# DP32G030 register map
File version: 1.0
CPU: CM0 r0p0, little endian, no MPU, no FPU, 4 interrupt priority bits
Registers are 32-bit, read-write, reset 0x0 unless marked. A register's access mark holds for its fields unless they carry their own. Offsets are from the block's base; [hi:lo] are bit positions.

## PORTCON — PORTCON unit
Base 0x400B0000
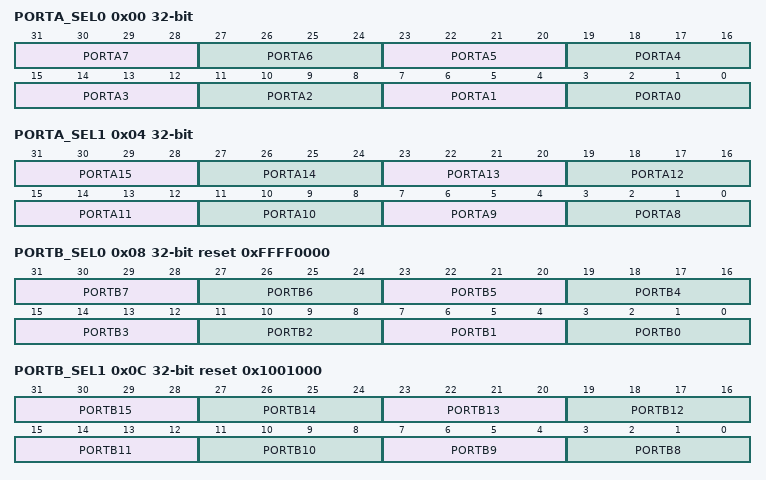
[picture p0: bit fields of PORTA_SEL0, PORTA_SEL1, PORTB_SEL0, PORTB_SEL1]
0x00 PORTA_SEL0 — PORTA Function Select Register0
  [31:28] PORTA7 — Port configuration 0000: GPIOA7 0001: UART1_TX 0010: timerp0_in0 0011: timerp0_out_l 0100: SARADC_CH2 0101: OPA0_VP
  [27:24] PORTA6 — Port configuration 0000: GPIOA6 0001: UART1_RTS 0010: TIMERP1_IN1 0011: timerp1_out_h 0100: SARADC_CH1 0101: OPA0_OUT
  [23:20] PORTA5 — Port configuration 0000: GPIOA5 0001: UART1_CTS 0010: PWMP1_PLUS1 0011: TIMERP1_IN0 0100: timerp1_out_l 0101: WAKEUP1 0110: SARADC_CH0
  [19:16] PORTA4 — Port configuration 000: GPIOA4 001: CMP0_VP 010: XTAH_XO
  [15:12] PORTA3 — Port configuration 000: GPIOA3 001: CMP0_VN
  [11:8] PORTA2 — Port configuration 000: GPIOA2 001: XTAL_XO
  [7:4] PORTA1 — Port configuration 000: GPIOA1 001: XTAL_XI
  [3:0] PORTA0 — 0000: GPIOA0 0001: PWMP1_PLUS0 0010: PWMP0_PLUS1 0011: TM 0100: WAKEUP0
0x04 PORTA_SEL1 — PORTA Function Select Register1
  [31:28] PORTA15 — 0000: GPIOA15 0001: PWMB1_CH1 0010: PWMP0_CH0 0011: TIMERP1_IN1 0100: timerp1_out_h
  [27:24] PORTA14 — 0000: GPIOA14 0001: PWMB1_CH0 0010: PWMP0_CH2N 0011: TIMERP1_IN0 0100: timerp1_out_l 0101: SARADC_CH9
  [23:20] PORTA13 — 0000: GPIOA13 0001: PWMB0_CH2 0010: PWMP0_CH1N 0011: timerp0_in1 0100: timerp0_out_h 0101: SARADC_CH8
  [19:16] PORTA12 — 0000: GPIOA12 0001: SPI0_MOSI 0010: PWMB0_CH1 0011: PWMP0_CH0N 0100: TIMERP0_IN0 0101: timerp0_out_l 0110: SARADC_CH7
  [15:12] PORTA11 — 0000: GPIOA11 0001: SPI0_MISO 0010: PWMB0_CH0 0011: PWMP0_BRAKE0 0100: TIMERP1_IN1 0101: timerp1_out_h 0110: SARADC_CH6
  [11:8] PORTA10 — 0000: GPIOA10 0001: SPI0_CLK 0010: SARADC_CH5 0011: CMP1_VP
  [7:4] PORTA9 — 0000: GPIOA9 0001: SPI0_SSN 0010: TIMERP1_IN0 0011: timerp1_out_l 0100: TM 0101: SARADC_CH4 0110: CMP1_VN
  [3:0] PORTA8 — 0000: GPIOA8 0001: UART1_RX 0010: timerp0_in1 0011: timerp0_out_h 0100: SARADC_CH3 0101: OPA0_VN
0x08 PORTB_SEL0 reset 0xFFFF0000 — PORTB Function Select Register0
  [31:28] PORTB7 — 0000: GPIOB7 0001: SPI0_SSN 0010: UART0_TX 0011: IIC0_SCL 0100: PWMP1_BRAKE0 0101: PWMP0_CH1
  [27:24] PORTB6 — 0000: GPIOB6 0001: PWMP0_CH0 0010: timerp0_in1 0011: timerp0_out_h
  [23:20] PORTB5 — 0000: GPIOB5 0001: SPI1_MOSI 0010: PWMP1_CH0N 0011: PWMP0_CH2N 0100: TIMERP0_IN0 0101: timerp0_out_l
  [19:16] PORTB4 — 0000: GPIOB4 0001: SPI1_MISO 0010: IIC1_SCL 0011: PWMP1_CH0 0100: PWMP0_CH1N 0101: timerp1_hall2
  [15:12] PORTB3 — 0000: GPIOB3 0001: SPI1_CLK 0010: IIC1_SDA 0011: PWMP0_CH0N 0100: TIMERP1_HALL1
  [11:8] PORTB2 — 0000: GPIOB2 0001: SPI1_SSN 0010: PWMP0_BRAKE1 0011: TIMERP1_HALL0
  [7:4] PORTB1 — 0000: GPIOB1 0001: UART2_RX 0010: IIC0_SDA 0011: PWMP0_CH2
  [3:0] PORTB0 — 0000: GPIOB0 0001: UART2_TX 0010: IIC0_SCL 0011: PWMB1_CH2 0100: PWMP0_CH1
0x0C PORTB_SEL1 reset 0x1001000 — PORTB Function Select Register1
  [31:28] PORTB15 — FUNCTION
  [27:24] PORTB14 — 0001:SWCLK
  [23:20] PORTB13 — FUNCTION
  [19:16] PORTB12 — FUNCTION
  [15:12] PORTB11 — 0001:SWDIO
  [11:8] PORTB10 — FUNCTION
  [7:4] PORTB9 — FUNCTION
  [3:0] PORTB8 — FUNCTION
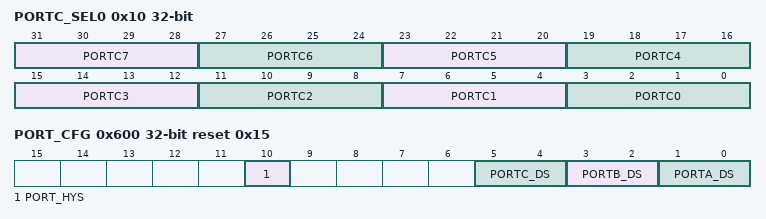
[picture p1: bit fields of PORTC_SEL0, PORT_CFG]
0x10 PORTC_SEL0 — PORTC Function Select Register0
  [31:28] PORTC7 — 0000: GPIOC7 0001: IIC1_SDA 0010: PWMP1_CH2 0011: TIMERP1_IN0 0100: timerp1_out_l 0101: OPA1_OUT
  [27:24] PORTC6 — 0000: GPIOC6 0001: IIC1_SCL 0010: PWMP1_CH1 0011: TIMERP1_IN1 0100: timerp1_out_h 0101: OPA1_VN
  [23:20] PORTC5 — 0000: GPIOC5 0001: timerp0_hall2 0010: TM 0011: OPA1_VP
  [19:16] PORTC4 — 0000: GPIOC4 0001: UART0_RX 0010: IIC0_SDA 0011: PWMP1_CH2N 0100: TIMERP0_HALL1 0101: CMP2_VP
  [15:12] PORTC3 — 0000: GPIOC3 0001: UART0_TX 0010: IIC0_SCL 0011: PWMP1_CH1N 0100: TIMERP0_HALL0 0101: CMP2_VN
  [11:8] PORTC2 — 0000: GPIOC2 0001: SPI1_MOSI 0010: PWMB1_CH2 0011: PWMP1_BRAKE2 0100: TIMERP0_IN1 0101: timerp0_out_h
  [7:4] PORTC1 — 0000: GPIOC1 0001: SPI1_MISO 0010: UART2_RTS 0011: PWMB1_CH1 0100: TIMERP0_IN0 0101: timerp0_out_l
  [3:0] PORTC0 — 0000: GPIOC0 0001: SPI1_CLK 0010: UART2_CTS 0011: PWMB1_CH0
0x100 PORTA_IE — PORTA Input enable register
  [15:0] PORTA_IE — PORTA Input Enable Register 0: disable 1: Enable (each bit corresponds to 1 IO, bit0 corresponds to A0, bit1 corresponds to A1)
0x104 PORTB_IE reset 0x4800 — PORTB Input enable register
  [15:0] PORTB_IE — PORTB Input Enable Register 0: disable 1: Enable (each bit corresponds to 1 IO, bit0 corresponds to B0, bit1 corresponds to B1)
0x108 PORTC_IE reset 0x20 — PORTC Input enable register
  [7:0] PORTC_IE — PORTC Input Enable Register 0: disable 1: Enable (each bit corresponds to 1 IO, bit0 corresponds to C0, bit1 corresponds to C1)
0x200 PORTA_PU — PORTA pull-up enable register
  [15:0] PORTA_PU — PORTA Pull-up Enable Register 0: disable 1: Enable (each bit corresponds to 1 IO, bit0 corresponds to A0, bit1 corresponds to A1)
0x204 PORTB_PU — PORTB pull-up enable register
  [15:0] PORTB_PU — PORTB Pull-up Enable Register 0: disable 1: Enable (each bit corresponds to 1 IO, bit0 corresponds to B0, bit1 corresponds to B1)
0x208 PORTC_PU — PORTC pull-up enable register
  [7:0] PORTC_PU — PORTC Pull-up Enable Register 0: disable 1: Enable (each bit corresponds to 1 IO, bit0 corresponds to C0, bit1 corresponds to C1)
0x300 PORTA_PD — PORTA pull-down enable register
  [15:0] PORTA_PD — PORTA Pull-down Enable Register 0: disable 1: Enable (each bit corresponds to 1 IO, bit0 corresponds to A0, bit1 corresponds to A1)
0x304 PORTB_PD — PORTB pull-down enable register
  [15:0] PORTB_PD — PORTB Pull-down Enable Register 0: disable 1: Enable (each bit corresponds to 1 IO, bit0 corresponds to B0, bit1 corresponds to B1)
0x308 PORTC_PD reset 0x20 — PORTC pull-down enable register
  [7:0] PORTC_PD — PORTC Pull-down Enable Register 0: disable 1: Enable (each bit corresponds to 1 IO, bit0 corresponds to C0, bit1 corresponds to C1)
0x400 PORTA_OD — PORTA Open Drain Enable Register
  [15:0] PORTA_OD — PORTA Open Drain Enable Register 0: disable 1: Enable (each bit corresponds to 1 IO, bit0 corresponds to A0, bit1 corresponds to A1)
0x404 PORTB_OD — PORTB Open Drain Enable Register
  [15:0] PORTB_OD — PORTB Open Drain Enable Register 0: disable 1: Enable (each bit corresponds to 1 IO, bit0 corresponds to B0, bit1 corresponds to B1)
0x408 PORTC_OD — PORTC Open Drain Enable Register
  [7:0] PORTC_OD — PORTC Open Drain Enable Register 0: disable 1: Enable (each bit corresponds to 1 IO, bit0 corresponds to C0, bit1 corresponds to C1)
0x500 PORTA_WKE — PORTA wakeup enable register
  [15:0] PORTA_WKE — PORTA Wake-up Enable Register 0: disable 1: Enable (each bit corresponds to 1 IO, bit0 corresponds to A0, bit1 corresponds to A1)
0x504 PORTB_WKE — PORTB wakeup enable register
  [15:0] PORTB_WKE — PORTB Wake-up Enable Register 0: disable 1: Enable (each bit corresponds to 1 IO, bit0 corresponds to B0, bit1 corresponds to B1)
0x508 PORTC_WKE — PORTC wakeup enable register
  [7:0] PORTC_WKE — PORTC Wake-up Enable Register 0: disable 1: Enable (each bit corresponds to 1 IO, bit0 corresponds to C0, bit1 corresponds to C1)
0x600 PORT_CFG reset 0x15 — port configuration register
  [10] PORT_HYS — PORT Input hysteresis level selection 0: low input hysteresis (input signal greater than 0.7VDD and less than 0.3VDD) 1: high input hysteresis (input signal greater than 0.85VDD and less than 0.15VDD)
  [5:4] PORTC_DS — PORTC Driveability Selection Register 00: 5mA 01: 10mA 10: 15mA 11: 20mA
  [3:2] PORTB_DS — PORTB Drive capability selection register 00: 5mA 01: 10mA 10: 15mA 11: 20mA
  [1:0] PORTA_DS — PORTA Driveability Selection Register 00: 5mA 01: 10mA 10: 15mA 11: 20mA
0x700 PORTA_WK_SEL — PORTA Wake-up IO Along Select Register
  [15:0] PORTA_WK_SEL — PORTA wake-up function is configured along 0: PORTA wake-up function active on falling edge 1: PORTA wake-up function rising edge active
0x704 PORTB_WK_SEL — PORTB Wake-up IO Along Select Register
  [15:0] PORTB_WK_SEL — PORTB wake-up function is configured along 0: PORTB wake-up function active on falling edge 1: PORTB wake-up function rising edge active
0x708 PORTC_WK_SEL — PORTC Wake-Up IO Along Select Register
  [7:0] PORTC_WK_SEL — PORTC wake-up function is configured along 0: PORTC wake-up function active on falling edge 1: PORTC wake-up function rising edge active
